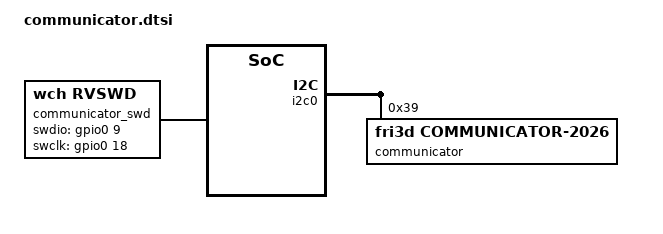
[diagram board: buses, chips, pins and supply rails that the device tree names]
/*
 * Copyright (c) 2026 Bert Outtier <outtierbert@gmail.com>
 *
 * SPDX-License-Identifier: Apache-2.0
 *
 * Communicator 2026 add-on on the Fri3d badge's expansion connector (2026
 * badge: main I2C on IO9/IO18, UART0 RX on IO44, 3V3_AUX). It sends its HID
 * key reports on the UART.
 */

#include <zephyr/dt-bindings/gpio/gpio.h>
#include <zephyr/dt-bindings/input/input-event-codes.h>
#include <zephyr/dt-bindings/input/keymap.h>

/ {
	/*
	 * Debug interface of the add-on, to update its firmware: its I2C pins
	 * become SWD after the remap command, and go back to I2C0 when the
	 * session ends.
	 */
	communicator_swd: communicator-swd {
		compatible = "wch,rvswd";
		swdio-gpios = <&gpio0 9 GPIO_ACTIVE_HIGH>;  /* IO9, I2C0 SDA */
		swclk-gpios = <&gpio0 18 GPIO_ACTIVE_HIGH>; /* IO18, I2C0 SCL */
		pinctrl-0 = <&i2c0_default>;
		pinctrl-names = "default";
	};
};

&i2c0 {
	communicator: communicator@39 {
		compatible = "fri3d,communicator-2026";
		reg = <0x39>;
		uart = <&uart0>;
		rvswd = <&communicator_swd>;

		/*
		 * The keyboard as input events (with CONFIG_INPUT), the add-on
		 * firmware's layout. No FN key (row 3, column 7): the firmware
		 * keeps FN and its combinations out of the matrix.
		 */
		communicator_input: input {
			compatible = "fri3d,communicator-2026-input";
			keymap = <MATRIX_KEY(0, 0, INPUT_KEY_ESC)
				  MATRIX_KEY(0, 1, INPUT_KEY_F1)
				  MATRIX_KEY(0, 2, INPUT_KEY_F2)
				  MATRIX_KEY(0, 3, INPUT_KEY_F3)
				  MATRIX_KEY(0, 4, INPUT_KEY_F4)
				  MATRIX_KEY(0, 5, INPUT_KEY_F5)
				  MATRIX_KEY(0, 6, INPUT_KEY_F6)
				  MATRIX_KEY(0, 7, INPUT_KEY_BACKSPACE)
				  MATRIX_KEY(0, 8, INPUT_KEY_GRAVE)
				  MATRIX_KEY(1, 0, INPUT_KEY_1)
				  MATRIX_KEY(1, 1, INPUT_KEY_2)
				  MATRIX_KEY(1, 2, INPUT_KEY_3)
				  MATRIX_KEY(1, 3, INPUT_KEY_4)
				  MATRIX_KEY(1, 4, INPUT_KEY_5)
				  MATRIX_KEY(1, 5, INPUT_KEY_6)
				  MATRIX_KEY(1, 6, INPUT_KEY_7)
				  MATRIX_KEY(1, 7, INPUT_KEY_8)
				  MATRIX_KEY(1, 8, INPUT_KEY_9)
				  MATRIX_KEY(2, 0, INPUT_KEY_0)
				  MATRIX_KEY(2, 1, INPUT_KEY_MINUS)
				  MATRIX_KEY(2, 2, INPUT_KEY_EQUAL)
				  MATRIX_KEY(2, 3, INPUT_KEY_TAB)
				  MATRIX_KEY(2, 4, INPUT_KEY_Q)
				  MATRIX_KEY(2, 5, INPUT_KEY_W)
				  MATRIX_KEY(2, 6, INPUT_KEY_E)
				  MATRIX_KEY(2, 7, INPUT_KEY_R)
				  MATRIX_KEY(2, 8, INPUT_KEY_T)
				  MATRIX_KEY(3, 0, INPUT_KEY_Y)
				  MATRIX_KEY(3, 1, INPUT_KEY_U)
				  MATRIX_KEY(3, 2, INPUT_KEY_I)
				  MATRIX_KEY(3, 3, INPUT_KEY_O)
				  MATRIX_KEY(3, 4, INPUT_KEY_P)
				  MATRIX_KEY(3, 5, INPUT_KEY_LEFTBRACE)
				  MATRIX_KEY(3, 6, INPUT_KEY_RIGHTBRACE)
				  MATRIX_KEY(3, 8, INPUT_KEY_A)
				  MATRIX_KEY(4, 0, INPUT_KEY_S)
				  MATRIX_KEY(4, 1, INPUT_KEY_D)
				  MATRIX_KEY(4, 2, INPUT_KEY_F)
				  MATRIX_KEY(4, 3, INPUT_KEY_G)
				  MATRIX_KEY(4, 4, INPUT_KEY_H)
				  MATRIX_KEY(4, 5, INPUT_KEY_J)
				  MATRIX_KEY(4, 6, INPUT_KEY_K)
				  MATRIX_KEY(4, 7, INPUT_KEY_L)
				  MATRIX_KEY(4, 8, INPUT_KEY_SEMICOLON)
				  MATRIX_KEY(5, 0, INPUT_KEY_APOSTROPHE)
				  MATRIX_KEY(5, 1, INPUT_KEY_ENTER)
				  MATRIX_KEY(5, 2, INPUT_KEY_LEFTSHIFT)
				  MATRIX_KEY(5, 3, INPUT_KEY_Z)
				  MATRIX_KEY(5, 4, INPUT_KEY_X)
				  MATRIX_KEY(5, 5, INPUT_KEY_C)
				  MATRIX_KEY(5, 6, INPUT_KEY_V)
				  MATRIX_KEY(5, 7, INPUT_KEY_B)
				  MATRIX_KEY(5, 8, INPUT_KEY_N)
				  MATRIX_KEY(6, 0, INPUT_KEY_M)
				  MATRIX_KEY(6, 1, INPUT_KEY_COMMA)
				  MATRIX_KEY(6, 2, INPUT_KEY_DOT)
				  MATRIX_KEY(6, 3, INPUT_KEY_SLASH)
				  MATRIX_KEY(6, 4, INPUT_KEY_UP)
				  MATRIX_KEY(6, 5, INPUT_KEY_RIGHTSHIFT)
				  MATRIX_KEY(6, 6, INPUT_KEY_LEFTCTRL)
				  MATRIX_KEY(6, 7, INPUT_KEY_LEFTMETA)
				  MATRIX_KEY(6, 8, INPUT_KEY_LEFTALT)
				  MATRIX_KEY(7, 0, INPUT_KEY_BACKSLASH)
				  MATRIX_KEY(7, 1, INPUT_KEY_SPACE)
				  MATRIX_KEY(7, 2, INPUT_KEY_SPACE)
				  MATRIX_KEY(7, 3, INPUT_KEY_SPACE)
				  MATRIX_KEY(7, 4, INPUT_KEY_RIGHTALT)
				  MATRIX_KEY(7, 5, INPUT_KEY_LEFT)
				  MATRIX_KEY(7, 6, INPUT_KEY_DOWN)
				  MATRIX_KEY(7, 7, INPUT_KEY_RIGHT)>;
		};
	};
};
